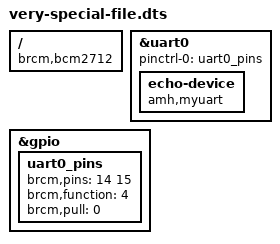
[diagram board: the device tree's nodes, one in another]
/dts-v1/;
/plugin/;

/ {
    compatible = "brcm,bcm2712";

    fragment@0 {
        target = <&uart0>;
        __overlay__ {
            status = "okay";
            pinctrl-names = "default";
            pinctrl-0 = <&uart0_pins>;
            
            echo-device {
                compatible = "amh,myuart";
                status = "okay";
            };
        };
    };

    fragment@1 {
        target = <&gpio>;
        __overlay__ {
            uart0_pins: uart0_pins {
                brcm,pins = <14 15>;
                brcm,function = <4>; /* alt0 */
                brcm,pull = <0>; /* no pull */
            };
        };
    };
};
